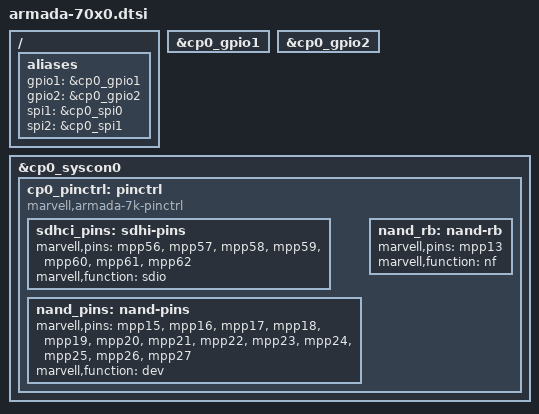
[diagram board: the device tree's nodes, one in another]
// SPDX-License-Identifier: (GPL-2.0+ OR MIT)
/*
 * Copyright (C) 2017 Marvell Technology Group Ltd.
 *
 * Device Tree file for the Armada 70x0 SoC
 */

/*
 * Instantiate the CP110
 */
#define CP110_NUM				0
#define CP110_BASE				0xf2000000
#define CP110_PCIE_MEM_SIZE			0xf00000
#define CP110_PCIEx_CPU_IO_BASE(iface)		(0xf9000000 + (iface) *  0x10000)
#define CP110_PCIEx_CPU_MEM_BASE(iface)		(0xf6000000 + (iface) *  0x1000000)
#define CP110_PCIEx_BUS_IO_BASE(iface)		(CP110_PCIEx_CPU_IO_BASE(iface))
#define CP110_PCIEx_BUS_MEM_BASE(iface)		(CP110_PCIEx_CPU_MEM_BASE(iface))
#define CP110_PCIE_BUS_MEM_CFG			(0x82000000)

#include "armada-cp110.dtsi"

#undef CP110_NUM
#undef CP110_BASE
#undef CP110_PCIE_MEM_SIZE
#undef CP110_PCIEx_CPU_IO_BASE
#undef CP110_PCIEx_CPU_MEM_BASE
#undef CP110_PCIEx_BUS_IO_BASE
#undef CP110_PCIEx_BUS_MEM_BASE
#undef CP110_PCIE_BUS_MEM_CFG

/ {
	aliases {
		gpio1 = &cp0_gpio1;
		gpio2 = &cp0_gpio2;
		spi1 = &cp0_spi0;
		spi2 = &cp0_spi1;
	};
};



&cp0_gpio1 {
	status = "okay";
};

&cp0_gpio2 {
	status = "okay";
};

&cp0_syscon0 {
	cp0_pinctrl: pinctrl {
		compatible = "marvell,armada-7k-pinctrl";

		sdhci_pins: sdhi-pins {
			marvell,pins = "mpp56", "mpp57", "mpp58",
				       "mpp59", "mpp60", "mpp61", "mpp62";
			marvell,function = "sdio";
		};

		nand_pins: nand-pins {
			marvell,pins =
			"mpp15", "mpp16", "mpp17", "mpp18",
			"mpp19", "mpp20", "mpp21", "mpp22",
			"mpp23", "mpp24", "mpp25", "mpp26",
			"mpp27";
			marvell,function = "dev";
		};

		nand_rb: nand-rb {
			marvell,pins = "mpp13";
			marvell,function = "nf";
		};
	};
};
